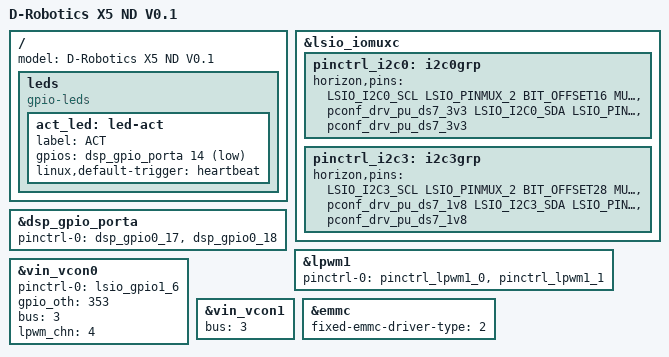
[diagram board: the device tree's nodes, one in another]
// SPDX-License-Identifier: GPL-2.0
/*
 * dts for Sunrise5 EVB-V2 platform
 *
 * Copyright (C) 2024 Horizon Robotics Inc.
 *
 */

/dts-v1/;
#include "x5-rdk.dtsi"

/ {
	model = "D-Robotics X5 ND V0.1";

	leds {
		status = "okay";
		compatible = "gpio-leds";

		act_led: led-act {
			label = "ACT";
			gpios = <&dsp_gpio_porta 14 GPIO_ACTIVE_LOW>;
			linux,default-trigger = "heartbeat";
		};
	};

};

&lsio_iomuxc {
	pinctrl_i2c0: i2c0grp {
		horizon,pins = <
			LSIO_I2C0_SCL  LSIO_PINMUX_2 BIT_OFFSET16  MUX_ALT0 &pconf_drv_pu_ds7_3v3
			LSIO_I2C0_SDA  LSIO_PINMUX_2 BIT_OFFSET18  MUX_ALT0 &pconf_drv_pu_ds7_3v3
		>;
	};

	pinctrl_i2c3: i2c3grp {
		horizon,pins = <
			LSIO_I2C3_SCL  LSIO_PINMUX_2 BIT_OFFSET28  MUX_ALT0 &pconf_drv_pu_ds7_1v8
			LSIO_I2C3_SDA  LSIO_PINMUX_2 BIT_OFFSET30  MUX_ALT0 &pconf_drv_pu_ds7_1v8
		>;
	};
};

//wifi antenna Onboard
&dsp_gpio_porta {
	pinctrl-names = "default";
	pinctrl-0 = < &dsp_gpio0_17
				  &dsp_gpio0_18
				>;
};

&lpwm1 {
	status = "okay";
	pinctrl-names = "default";
	/** for display backlight **/
	pinctrl-0 = <&pinctrl_lpwm1_0 &pinctrl_lpwm1_1>;
};

&vin_vcon0 {
	status = "okay";
	/* camera sensor
	 * reset gpio:	LSIO_GPIO1_PIN6:	353
	 * lpwm      :  LSIO_SPI3_SCLK  :   pinctrl_lpwm1_0
	 */
	pinctrl-names = "default";
	pinctrl-0 = <&lsio_gpio1_6>;
	gpio_oth = <353>;   // reset gpio
	bus = <3>; // i2c bus
	lpwm_chn = <4>;
};

&vin_vcon1 {
	status = "okay";
	// use same sensor gpio with vcon0 and i2c bus
	bus = <3>;
};

&emmc {
	status = "okay";
	fixed-emmc-driver-type = <2>;
};
